AUTOSAR XML (schema 4.0)
package /BMS/PortInterfaces
  15 x sender receiver interface:
    CellMeasurements_I  # Validated cell voltages and cell temperatures, one sample per 10 ms cycle.
      data cellVoltages_mV: type=uint16
      data cellTemperatures_dC: type=sint16
      data measurementValid: type=boolean
    PackVoltage_I  # Pack voltage as the sum of the validated cell voltages.
      data packVoltage_mV: type=uint32
    PackCurrent_I  # Signed pack current, discharge positive, sampled at 1 ms.
      data packCurrent_mA: type=sint32
      data currentValid: type=boolean
    OvercurrentCondition_I  # Debounced overcurrent condition after the 100 ms persistence window.
      data overcurrentActive: type=boolean
    ContactorCommand_I  # Open command from the safety supervisor to the contactor drivers.
      data openCommand: type=boolean
    ProtectionFault_I  # Latched cell-protection fault with the cell, the limit and the measured value.
      4 x data:
        faultActive: type=boolean
        cellId: type=uint8
        limitId: type=uint8
        measuredValue: type=sint32
    IsolationStatus_I  # Isolation resistance per volt of pack voltage and the derived isolation fault.
      data isolation_OhmPerVolt: type=uint32
      data isolationFault: type=boolean
    ChargeIntegral_I  # Charge integral of the pack current in ampere-seconds.
      data charge_As: type=sint32
    StateOfCharge_I  # Fused state-of-charge estimate in per mille of rated capacity.
      data soc_permille: type=uint16
    RemainingCapacity_I  # Remaining capacity of the pack; never increases over the life of the pack.
      data capacity_mAh: type=uint32
    EstimateValidity_I  # Trustworthiness verdict for the state-of-charge estimate.
      data estimateReliable: type=boolean
    BatteryState_I  # Vehicle-facing battery state frame, sent on a 100 ms cycle.
      data soc_permille: type=uint16
      data capacity_mAh: type=uint32
      data stateValid: type=boolean
    ThermalState_I  # Highest and lowest valid cell temperature and their spread.
      data highestCellTemp_dC: type=sint16
      data lowestCellTemp_dC: type=sint16
      data spread_dK: type=uint16
    ThermalRequest_I  # Cooling and heating request to the coolant pump and the pack heater.
      data coolingRequest: type=boolean
      data heatingRequest: type=boolean
      data requestId: type=uint8
    PowerLimit_I  # Permitted discharge power after thermal derating.
      data permittedDischargePower_W: type=uint32
package /BMS/SwComponentTypes
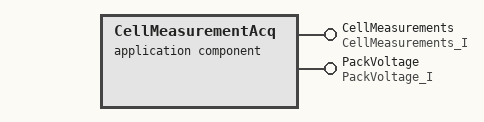
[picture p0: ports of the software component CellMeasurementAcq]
  application sw component type CellMeasurementAcq  # Reads all cell voltages and temperatures from the analogue front-end every 10 ms.
    provide port CellMeasurements: provided-interface=CellMeasurements_I
    provide port PackVoltage: provided-interface=PackVoltage_I
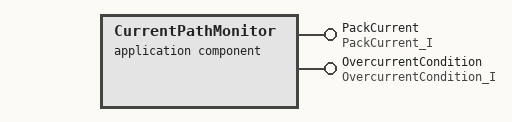
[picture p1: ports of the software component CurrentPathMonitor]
  application sw component type CurrentPathMonitor  # Samples the shunt amplifier at 1 ms and debounces the overcurrent condition over 100 ms.
    provide port PackCurrent: provided-interface=PackCurrent_I
    provide port OvercurrentCondition: provided-interface=OvercurrentCondition_I
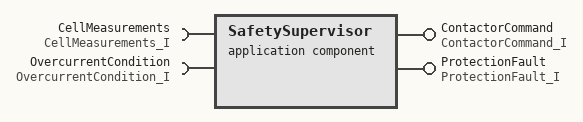
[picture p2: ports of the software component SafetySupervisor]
  application sw component type SafetySupervisor  # Single decision point of cell protection: evaluates limits, latches the fault, commands the contactors open.
    provide port ContactorCommand: provided-interface=ContactorCommand_I
    provide port ProtectionFault: provided-interface=ProtectionFault_I
    require port CellMeasurements: required-interface=CellMeasurements_I
    require port OvercurrentCondition: required-interface=OvercurrentCondition_I
  application sw component type ContactorActuator  # Drives the two contactor coils as a dual-channel low-side pair.
    require port ContactorCommand: required-interface=ContactorCommand_I
  application sw component type FaultMemory  # Stores cell-protection fault records in a non-volatile ring of 64 entries.
    require port ProtectionFault: required-interface=ProtectionFault_I
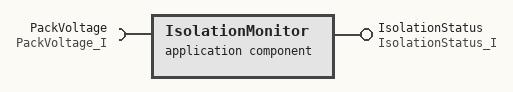
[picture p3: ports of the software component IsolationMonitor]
  application sw component type IsolationMonitor  # Reduces the insulation measurement and the pack voltage to ohm per volt and derives the isolation fault.
    provide port IsolationStatus: provided-interface=IsolationStatus_I
    require port PackVoltage: required-interface=PackVoltage_I
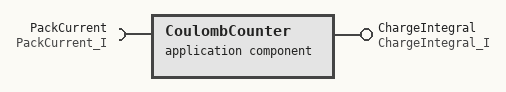
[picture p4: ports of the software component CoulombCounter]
  application sw component type CoulombCounter  # Integrates the signed pack current on a 10 ms tick.
    provide port ChargeIntegral: provided-interface=ChargeIntegral_I
    require port PackCurrent: required-interface=PackCurrent_I
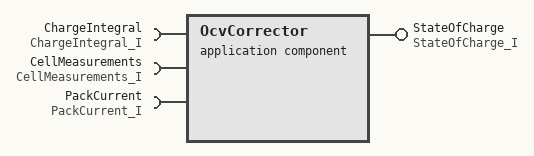
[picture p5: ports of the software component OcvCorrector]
  application sw component type OcvCorrector  # Anchors the state of charge on the open-circuit voltage after 30 minutes of rest.
    provide port StateOfCharge: provided-interface=StateOfCharge_I
    require port ChargeIntegral: required-interface=ChargeIntegral_I
    require port CellMeasurements: required-interface=CellMeasurements_I
    require port PackCurrent: required-interface=PackCurrent_I
  application sw component type SocStore  # Keeps the non-volatile shadow of the published state of charge.
    require port StateOfCharge: required-interface=StateOfCharge_I
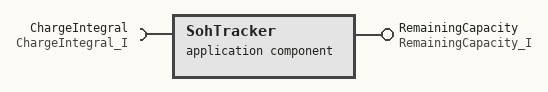
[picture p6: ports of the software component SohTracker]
  application sw component type SohTracker  # Derives the remaining capacity from the charge counted between two rest anchors.
    provide port RemainingCapacity: provided-interface=RemainingCapacity_I
    require port ChargeIntegral: required-interface=ChargeIntegral_I
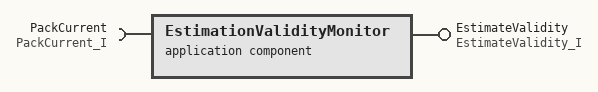
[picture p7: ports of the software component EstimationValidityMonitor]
  application sw component type EstimationValidityMonitor  # Flags the estimate unreliable when the pack current is stale for 5 seconds.
    provide port EstimateValidity: provided-interface=EstimateValidity_I
    require port PackCurrent: required-interface=PackCurrent_I
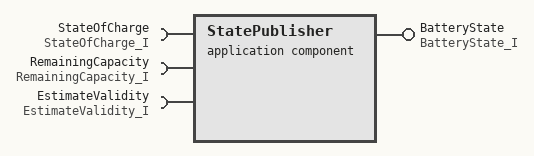
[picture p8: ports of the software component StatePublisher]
  application sw component type StatePublisher  # Sends the battery state frame to the vehicle every 100 ms.
    provide port BatteryState: provided-interface=BatteryState_I
    require port StateOfCharge: required-interface=StateOfCharge_I
    require port RemainingCapacity: required-interface=RemainingCapacity_I
    require port EstimateValidity: required-interface=EstimateValidity_I
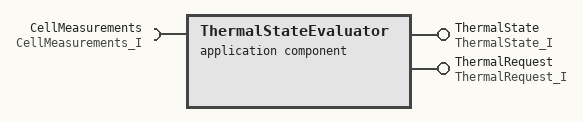
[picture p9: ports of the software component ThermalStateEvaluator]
  application sw component type ThermalStateEvaluator  # Reduces the cell temperatures to highest, lowest and spread and derives the thermal requests.
    provide port ThermalState: provided-interface=ThermalState_I
    provide port ThermalRequest: provided-interface=ThermalRequest_I
    require port CellMeasurements: required-interface=CellMeasurements_I
  application sw component type CoolantActuatorIf  # Forwards the thermal request to the coolant pump and the pack heater and supervises the acknowledgement.
    require port ThermalRequest: required-interface=ThermalRequest_I
  application sw component type PowerLimitCalculator  # Derates the permitted discharge power linearly between 55 and 60 degrees Celsius.
    provide port PowerLimit: provided-interface=PowerLimit_I
    require port ThermalState: required-interface=ThermalState_I
package /BMS/Compositions
  composition sw component type BmsApplication  # The BMS application composition: every software component and the data flow between them.
    15 x component:
      CellMeasurementAcq_Proto: type=CellMeasurementAcq
      CurrentPathMonitor_Proto: type=CurrentPathMonitor
      SafetySupervisor_Proto: type=SafetySupervisor
      ContactorActuator_Proto: type=ContactorActuator
      FaultMemory_Proto: type=FaultMemory
      IsolationMonitor_Proto: type=IsolationMonitor
      CoulombCounter_Proto: type=CoulombCounter
      OcvCorrector_Proto: type=OcvCorrector
      SocStore_Proto: type=SocStore
      SohTracker_Proto: type=SohTracker
      EstimationValidityMonitor_Proto: type=EstimationValidityMonitor
      StatePublisher_Proto: type=StatePublisher
      ThermalStateEvaluator_Proto: type=ThermalStateEvaluator
      CoolantActuatorIf_Proto: type=CoolantActuatorIf
      PowerLimitCalculator_Proto: type=PowerLimitCalculator
    connect CellMeasurementAcq_Proto.CellMeasurements -> SafetySupervisor_Proto.CellMeasurements
    connect CurrentPathMonitor_Proto.OvercurrentCondition -> SafetySupervisor_Proto.OvercurrentCondition
    connect SafetySupervisor_Proto.ContactorCommand -> ContactorActuator_Proto.ContactorCommand
    connect SafetySupervisor_Proto.ProtectionFault -> FaultMemory_Proto.ProtectionFault
    connect CellMeasurementAcq_Proto.PackVoltage -> IsolationMonitor_Proto.PackVoltage
    connect CurrentPathMonitor_Proto.PackCurrent -> CoulombCounter_Proto.PackCurrent
    connect CoulombCounter_Proto.ChargeIntegral -> OcvCorrector_Proto.ChargeIntegral
    connect CellMeasurementAcq_Proto.CellMeasurements -> OcvCorrector_Proto.CellMeasurements
    connect CurrentPathMonitor_Proto.PackCurrent -> OcvCorrector_Proto.PackCurrent
    connect OcvCorrector_Proto.StateOfCharge -> SocStore_Proto.StateOfCharge
    connect CoulombCounter_Proto.ChargeIntegral -> SohTracker_Proto.ChargeIntegral
    connect CurrentPathMonitor_Proto.PackCurrent -> EstimationValidityMonitor_Proto.PackCurrent
    connect OcvCorrector_Proto.StateOfCharge -> StatePublisher_Proto.StateOfCharge
    connect SohTracker_Proto.RemainingCapacity -> StatePublisher_Proto.RemainingCapacity
    connect EstimationValidityMonitor_Proto.EstimateValidity -> StatePublisher_Proto.EstimateValidity
    connect CellMeasurementAcq_Proto.CellMeasurements -> ThermalStateEvaluator_Proto.CellMeasurements
    connect ThermalStateEvaluator_Proto.ThermalRequest -> CoolantActuatorIf_Proto.ThermalRequest
    connect ThermalStateEvaluator_Proto.ThermalState -> PowerLimitCalculator_Proto.ThermalState
